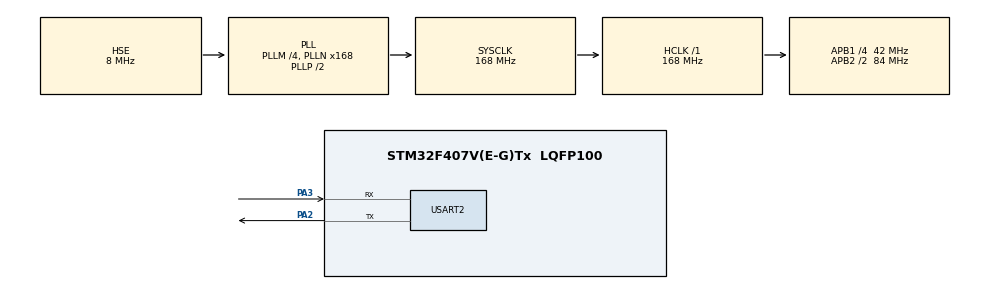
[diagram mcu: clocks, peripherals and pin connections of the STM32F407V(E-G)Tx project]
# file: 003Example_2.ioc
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FREERTOS.Tasks01=defaultTask,0,128,StartDefaultTask,Default,NULL,Dynamic,NULL,NULL
Mcu.Family=STM32F4
Mcu.Name=STM32F407V(E-G)Tx
Mcu.Package=LQFP100
NVIC.PriorityGroup=NVIC_PRIORITYGROUP_4
NVIC.TIM1_UP_TIM10_IRQn=true\:15\:0\:false\:false\:true\:false\:false\:true\:true
NVIC.TimeBase=TIM1_UP_TIM10_IRQn
NVIC.TimeBaseIP=TIM1
NVIC.USART2_IRQn=true\:5\:0\:false\:false\:true\:true\:true\:true\:true
PA2.Mode=Asynchronous
PA2.Signal=USART2_TX
PA3.Mode=Asynchronous
PA3.Signal=USART2_RX
PH0-OSC_IN.Mode=HSE-External-Oscillator
PH0-OSC_IN.Signal=RCC_OSC_IN
PH1-OSC_OUT.Mode=HSE-External-Oscillator
PH1-OSC_OUT.Signal=RCC_OSC_OUT
ProjectManager.HeapSize=0x200
ProjectManager.StackSize=0x400
ProjectManager.TargetToolchain=STM32CubeIDE
RCC.48MHZClocksFreq_Value=84000000
RCC.AHBFreq_Value=168000000
RCC.APB1CLKDivider=RCC_HCLK_DIV4
RCC.APB1Freq_Value=42000000
RCC.APB1TimFreq_Value=84000000
RCC.APB2CLKDivider=RCC_HCLK_DIV2
RCC.APB2Freq_Value=84000000
RCC.APB2TimFreq_Value=168000000
RCC.CortexFreq_Value=168000000
RCC.HCLKFreq_Value=168000000
RCC.HSE_VALUE=8000000
RCC.HSI_VALUE=16000000
RCC.LSE_VALUE=32768
RCC.PLLM=4
RCC.PLLN=168
RCC.PLLSourceVirtual=RCC_PLLSOURCE_HSE
RCC.SYSCLKFreq_VALUE=168000000
RCC.SYSCLKSource=RCC_SYSCLKSOURCE_PLLCLK
RCC.VCOOutputFreq_Value=336000000
USART2.VirtualMode=VM_ASYNC
VP_FREERTOS_VS_CMSIS_V1.Mode=CMSIS_V1
VP_SYS_VS_tim1.Mode=TIM1
board=custom

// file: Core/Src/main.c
/* USER CODE BEGIN Header */
/**
 ******************************************************************************
 * @file           : main.c
 * @brief          : Main program body
 ******************************************************************************
 * @attention
 *
 * Copyright (c) 2024 STMicroelectronics.
 * All rights reserved.
 *
 * This software is licensed under terms that can be found in the LICENSE file
 * in the root directory of this software component.
 * If no LICENSE file comes with this software, it is provided AS-IS.
 *
 ******************************************************************************
 */
/* USER CODE END Header */
#include "main.h"
#include "cmsis_os.h"

/* USER CODE BEGIN Includes */
#include "FreeRTOS.h"
#include "task.h"
#include "timers.h"
#include "queue.h"
#include "semphr.h"
#include "event_groups.h"

#include "stdio.h"
#include "string.h"

/* USER CODE END Includes */

UART_HandleTypeDef huart2;

void SystemClock_Config(void);
static void MX_GPIO_Init(void);
static void MX_USART2_UART_Init(void);

/* USER CODE BEGIN 0 */
TaskHandle_t TaskHigh_Handler;
TaskHandle_t Medium_Handler;
TaskHandle_t TaskLow_Handler;

SemaphoreHandle_t Semaphore_Binary;

void TaskHigh(void *argument);
void TaskNormal(void *argument);
void TaskLow(void *argument);

/* USER CODE END 0 */

int main(void)
{

  /* MCU Configuration--------------------------------------------------------*/

  /* Reset of all peripherals, Initializes the Flash interface and the Systick. */
  HAL_Init();

  /* Configure the system clock */
  SystemClock_Config();

  /* Initialize all configured peripherals */
  MX_GPIO_Init();
  MX_USART2_UART_Init();
  /* USER CODE BEGIN 2 */
  Semaphore_Binary = xSemaphoreCreateBinary();

  if (Semaphore_Binary == NULL)
  {
    HAL_UART_Transmit(&huart2, (uint8_t *)"Unable semaphore\n", 17, 100);
  }
  else
  {
    HAL_UART_Transmit(&huart2, (uint8_t *)"Semaphore success\n", 18, 100);
    xSemaphoreGive(Semaphore_Binary);
  }

  xTaskCreate(TaskHigh, "High-Task", 128, NULL, 3, &TaskHigh_Handler);
  xTaskCreate(TaskNormal, "Normal-Task", 128, NULL, 2, &Medium_Handler);
  xTaskCreate(TaskLow, "Low-Task", 128, NULL, 1, &TaskLow_Handler);

  vTaskStartScheduler();

  /* USER CODE END 2 */

  /* Infinite loop */
  while (1)
  {

  }
}

void SystemClock_Config(void)
{
  RCC_OscInitTypeDef RCC_OscInitStruct = {0};
  RCC_ClkInitTypeDef RCC_ClkInitStruct = {0};

  /** Configure the main internal regulator output voltage
   */
  __HAL_RCC_PWR_CLK_ENABLE();
  __HAL_PWR_VOLTAGESCALING_CONFIG(PWR_REGULATOR_VOLTAGE_SCALE1);

  /** Initializes the RCC Oscillators according to the specified parameters
   * in the RCC_OscInitTypeDef structure.
   */
  RCC_OscInitStruct.OscillatorType = RCC_OSCILLATORTYPE_HSE;
  RCC_OscInitStruct.HSEState = RCC_HSE_ON;
  RCC_OscInitStruct.PLL.PLLState = RCC_PLL_ON;
  RCC_OscInitStruct.PLL.PLLSource = RCC_PLLSOURCE_HSE;
  RCC_OscInitStruct.PLL.PLLM = 4;
  RCC_OscInitStruct.PLL.PLLN = 168;
  RCC_OscInitStruct.PLL.PLLP = RCC_PLLP_DIV2;
  RCC_OscInitStruct.PLL.PLLQ = 4;
  if (HAL_RCC_OscConfig(&RCC_OscInitStruct) != HAL_OK)
  {
    Error_Handler();
  }

  /** Initializes the CPU, AHB and APB buses clocks
   */
  RCC_ClkInitStruct.ClockType = RCC_CLOCKTYPE_HCLK | RCC_CLOCKTYPE_SYSCLK | RCC_CLOCKTYPE_PCLK1 | RCC_CLOCKTYPE_PCLK2;
  RCC_ClkInitStruct.SYSCLKSource = RCC_SYSCLKSOURCE_PLLCLK;
  RCC_ClkInitStruct.AHBCLKDivider = RCC_SYSCLK_DIV1;
  RCC_ClkInitStruct.APB1CLKDivider = RCC_HCLK_DIV4;
  RCC_ClkInitStruct.APB2CLKDivider = RCC_HCLK_DIV2;

  if (HAL_RCC_ClockConfig(&RCC_ClkInitStruct, FLASH_LATENCY_5) != HAL_OK)
  {
    Error_Handler();
  }
}

static void MX_USART2_UART_Init(void)
{

  huart2.Instance = USART2;
  huart2.Init.BaudRate = 115200;
  huart2.Init.WordLength = UART_WORDLENGTH_8B;
  huart2.Init.StopBits = UART_STOPBITS_1;
  huart2.Init.Parity = UART_PARITY_NONE;
  huart2.Init.Mode = UART_MODE_TX_RX;
  huart2.Init.HwFlowCtl = UART_HWCONTROL_NONE;
  huart2.Init.OverSampling = UART_OVERSAMPLING_16;
  if (HAL_UART_Init(&huart2) != HAL_OK)
  {
    Error_Handler();
  }
}

static void MX_GPIO_Init(void)
{

  /* GPIO Ports Clock Enable */
  __HAL_RCC_GPIOH_CLK_ENABLE();
  __HAL_RCC_GPIOA_CLK_ENABLE();

}

/* USER CODE BEGIN 4 */
void TaskHigh(void *argument)
{
  while (1)
  {
    char *str = "Enter High Task\n";
    HAL_UART_Transmit(&huart2, (uint8_t *)str, strlen(str), 100);

    xSemaphoreTake(Semaphore_Binary, portMAX_DELAY);

    char *str2 = "Semaphore acquired by High_Task\n";
    HAL_UART_Transmit(&huart2, (uint8_t *)str2, strlen(str2), 100);

    char *str1 = "Leave and release High Task\n\n";
    HAL_UART_Transmit(&huart2, (uint8_t *)str1, strlen(str1), 100);
    xSemaphoreGive(Semaphore_Binary);
    vTaskDelay(1000);
  }
}

void TaskNormal(void *argument){
	while (1)
	  {
	    char *str1 = "Entered NormalTask\n";
	    HAL_UART_Transmit(&huart2, (uint8_t *)str1, strlen(str1), 100);

	    char *str2 = "Leaving NormalTask\n\n";
	    HAL_UART_Transmit(&huart2, (uint8_t *)str2, strlen(str2), 100);
	    vTaskDelay(1000);
	  }

}

void TaskLow(void *pvParematers)
{
  while (1)
  {
    char *str1 = "Entered LowTask and waiting for semaphore\n";
    HAL_UART_Transmit(&huart2, (uint8_t *)str1, strlen(str1), 100);

    if(HAL_GPIO_ReadPin(GPIOA, GPIO_PIN_0) == GPIO_PIN_SET) {
    	if(xSemaphoreTake(Semaphore_Binary, portMAX_DELAY) == pdTRUE){
    		char *str4 = "Button Press and Semaphore acquired by LowTask\n";
    		HAL_UART_Transmit(&huart2, (uint8_t*)str4, strlen(str4), 100);
    	}
    }
    else {
		char *str2 = "Leaving LowTask and releasing semaphore\n\n";
		HAL_UART_Transmit(&huart2, (uint8_t *)str2, strlen(str2), 100);
		xSemaphoreGive(Semaphore_Binary);

    }

    vTaskDelay(1000);
  }
}
/* USER CODE END 4 */

void HAL_TIM_PeriodElapsedCallback(TIM_HandleTypeDef *htim)
{
  if (htim->Instance == TIM1)
  {
    HAL_IncTick();
  }
}

void Error_Handler(void)
{
  __disable_irq();
  while (1)
  {
  }
}
